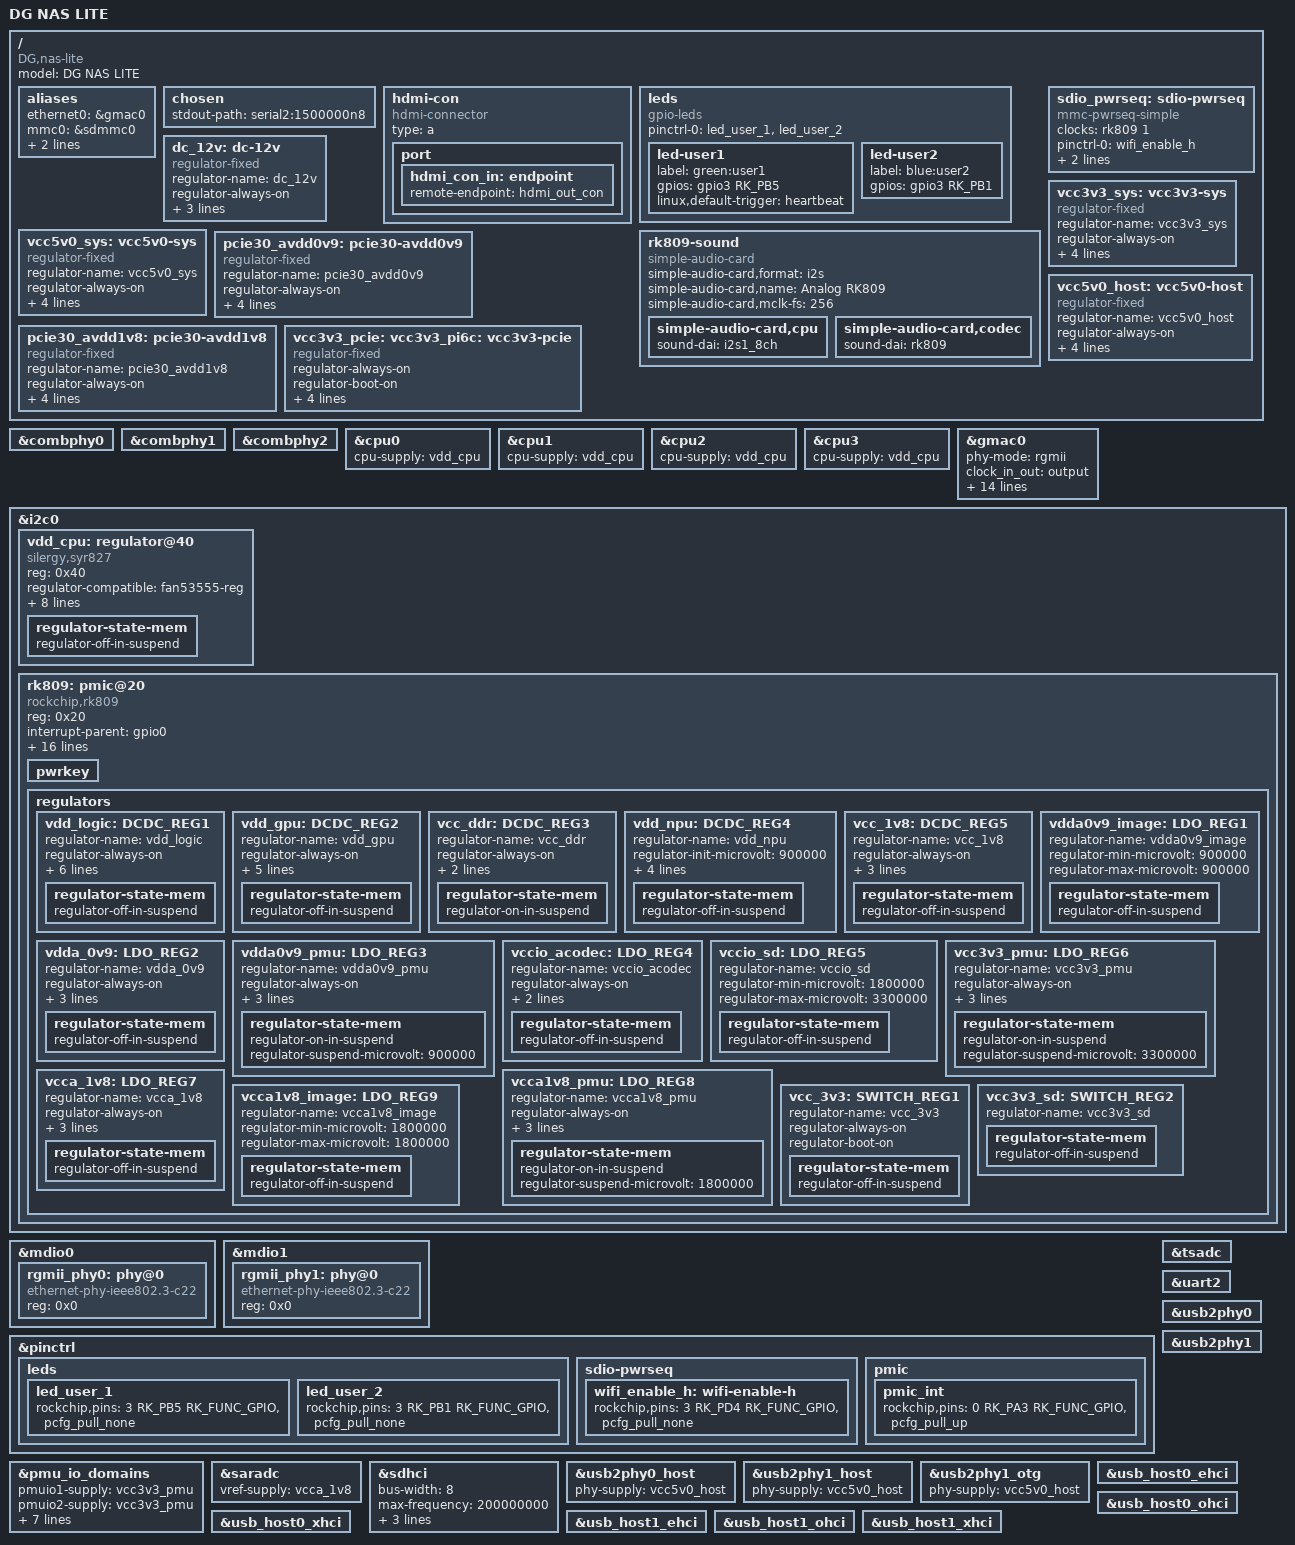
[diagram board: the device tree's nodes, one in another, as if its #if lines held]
// SPDX-License-Identifier: (GPL-2.0+ OR MIT)

/dts-v1/;
#include <dt-bindings/gpio/gpio.h>
#include <dt-bindings/leds/common.h>
#include <dt-bindings/pinctrl/rockchip.h>
#include <dt-bindings/soc/rockchip,vop2.h>
#include "rk3568.dtsi"

/ {
	model = "DG NAS LITE";
	compatible = "DG,nas-lite", "rockchip,rk3568";

	aliases {
		ethernet0 = &gmac0;
		mmc0 = &sdmmc0;
		mmc1 = &sdhci;
		mmc2 = &sdmmc1;
	};

	chosen: chosen {
		stdout-path = "serial2:1500000n8";
	};

#ifdef DTS_NO_LEGACY
	hdmi-con {
		compatible = "hdmi-connector";
		type = "a";

		port {
			hdmi_con_in: endpoint {
				remote-endpoint = <&hdmi_out_con>;
			};
		};
	};
#endif

	leds {
		compatible = "gpio-leds";
		pinctrl-names = "default";
		pinctrl-0 = <&led_user_1>, <&led_user_2>;

		led-user1 {
			label = "green:user1";
			gpios = <&gpio3 RK_PB5 GPIO_ACTIVE_HIGH>;
			linux,default-trigger = "heartbeat";
		};

		led-user2 {
			label = "blue:user2";
			gpios = <&gpio3 RK_PB1 GPIO_ACTIVE_HIGH>;
		};
	};

	rk809-sound {
		compatible = "simple-audio-card";
		simple-audio-card,format = "i2s";
		simple-audio-card,name = "Analog RK809";
		simple-audio-card,mclk-fs = <256>;

		simple-audio-card,cpu {
			sound-dai = <&i2s1_8ch>;
		};
		simple-audio-card,codec {
			sound-dai = <&rk809>;
		};
	};

	sdio_pwrseq: sdio-pwrseq {
		compatible = "mmc-pwrseq-simple";
		clocks = <&rk809 1>;
		clock-names = "ext_clock";
		pinctrl-names = "default";
		pinctrl-0 = <&wifi_enable_h>;
		reset-gpios = <&gpio3 RK_PD5 GPIO_ACTIVE_LOW>;
		post-power-on-delay-ms = <100>;
	};

	dc_12v: dc-12v {
		compatible = "regulator-fixed";
		regulator-name = "dc_12v";
		regulator-always-on;
		regulator-boot-on;
		regulator-min-microvolt = <12000000>;
		regulator-max-microvolt = <12000000>;
	};

	vcc3v3_sys: vcc3v3-sys {
		compatible = "regulator-fixed";
		regulator-name = "vcc3v3_sys";
		regulator-always-on;
		regulator-boot-on;
		regulator-min-microvolt = <3300000>;
		regulator-max-microvolt = <3300000>;
		vin-supply = <&dc_12v>;
	};

	vcc5v0_sys: vcc5v0-sys {
		compatible = "regulator-fixed";
		regulator-name = "vcc5v0_sys";
		regulator-always-on;
		regulator-boot-on;
		regulator-min-microvolt = <5000000>;
		regulator-max-microvolt = <5000000>;
		vin-supply = <&dc_12v>;
	};

	pcie30_avdd0v9: pcie30-avdd0v9 {
		compatible = "regulator-fixed";
		regulator-name = "pcie30_avdd0v9";
		regulator-always-on;
		regulator-boot-on;
		regulator-min-microvolt = <900000>;
		regulator-max-microvolt = <900000>;
		vin-supply = <&vcc3v3_sys>;
	};

	pcie30_avdd1v8: pcie30-avdd1v8 {
		compatible = "regulator-fixed";
		regulator-name = "pcie30_avdd1v8";
		regulator-always-on;
		regulator-boot-on;
		regulator-min-microvolt = <1800000>;
		regulator-max-microvolt = <1800000>;
		vin-supply = <&vcc3v3_sys>;
	};

	vcc3v3_pcie: vcc3v3_pi6c: vcc3v3-pcie {
		compatible = "regulator-fixed";
		regulator-always-on;
		regulator-boot-on;
		regulator-name = "vcc3v3_pcie";
		regulator-min-microvolt = <3300000>;
		regulator-max-microvolt = <3300000>;
		vin-supply = <&vcc5v0_sys>;
	};

	vcc5v0_host: vcc5v0-host {
		compatible = "regulator-fixed";
		regulator-name = "vcc5v0_host";
		regulator-always-on;
		regulator-boot-on;
		regulator-min-microvolt = <5000000>;
		regulator-max-microvolt = <5000000>;
		vin-supply = <&vcc5v0_sys>;
	};

};

&combphy0 {
	status = "okay";
};

&combphy1 {
	status = "okay";
};

&combphy2 {
	status = "okay";
};

&cpu0 {
	cpu-supply = <&vdd_cpu>;
};

&cpu1 {
	cpu-supply = <&vdd_cpu>;
};

&cpu2 {
	cpu-supply = <&vdd_cpu>;
};

&cpu3 {
	cpu-supply = <&vdd_cpu>;
};

&gmac0 {
	phy-mode = "rgmii";
	clock_in_out = "output";

	snps,reset-gpio = <&gpio3 RK_PA7 GPIO_ACTIVE_LOW>;
	snps,reset-active-low;
	/* Reset time is 20ms, 100ms for rtl8211f */
	snps,reset-delays-us = <0 20000 100000>;

	assigned-clocks = <&cru SCLK_GMAC0_RX_TX>, <&cru SCLK_GMAC0>;
	assigned-clock-parents = <&cru SCLK_GMAC0_RGMII_SPEED>;
	assigned-clock-rates = <0>, <125000000>;

	pinctrl-names = "default";
	pinctrl-0 = <&gmac0_miim
		     &gmac0_tx_bus2
		     &gmac0_rx_bus2
		     &gmac0_rgmii_clk
		     &gmac0_rgmii_bus
		     &gmac0_clkinout>;

	tx_delay = <0x3c>;
	rx_delay = <0x2f>;

	phy-handle = <&rgmii_phy0>;
	status = "okay";
};

&i2c0 {
	status = "okay";

	vdd_cpu: regulator@40 {
		compatible = "silergy,syr827";
		reg = <0x40>;
		regulator-compatible = "fan53555-reg";
		fcs,suspend-voltage-selector = <1>;
		regulator-name = "vdd_cpu";
		regulator-always-on;
		regulator-boot-on;
		regulator-min-microvolt = <712500>;
		regulator-max-microvolt = <1390000>;
		regulator-ramp-delay = <2300>;
		vin-supply = <&vcc5v0_sys>;

		regulator-state-mem {
			regulator-off-in-suspend;
		};
	};

	rk809: pmic@20 {
		compatible = "rockchip,rk809";
		reg = <0x20>;
		interrupt-parent = <&gpio0>;
		interrupts = <RK_PA3 IRQ_TYPE_LEVEL_LOW>;
		assigned-clocks = <&cru I2S1_MCLKOUT_TX>;
		assigned-clock-parents = <&cru CLK_I2S1_8CH_TX>;
		#clock-cells = <1>;
		clock-names = "mclk";
		clocks = <&cru I2S1_MCLKOUT_TX>;
		pinctrl-names = "default";
		pinctrl-0 = <&pmic_int>;
		rockchip,system-power-controller;
		#sound-dai-cells = <0>;
		vcc1-supply = <&vcc3v3_sys>;
		vcc2-supply = <&vcc3v3_sys>;
		vcc3-supply = <&vcc3v3_sys>;
		vcc4-supply = <&vcc3v3_sys>;
		vcc5-supply = <&vcc3v3_sys>;
		vcc6-supply = <&vcc3v3_sys>;
		vcc7-supply = <&vcc3v3_sys>;
		vcc8-supply = <&vcc3v3_sys>;
		vcc9-supply = <&vcc3v3_sys>;
		wakeup-source;
		pwrkey {
				status = "okay";
			};
		regulators {
			vdd_logic: DCDC_REG1 {
				regulator-name = "vdd_logic";
				regulator-always-on;
				regulator-boot-on;
				regulator-init-microvolt = <900000>;
				regulator-initial-mode = <0x2>;
				regulator-min-microvolt = <500000>;
				regulator-max-microvolt = <1350000>;
				regulator-ramp-delay = <6001>;

				regulator-state-mem {
					regulator-off-in-suspend;
				};
			};

			vdd_gpu: DCDC_REG2 {
				regulator-name = "vdd_gpu";
				regulator-always-on;
				regulator-init-microvolt = <900000>;
				regulator-initial-mode = <0x2>;
				regulator-min-microvolt = <500000>;
				regulator-max-microvolt = <1350000>;
				regulator-ramp-delay = <6001>;

				regulator-state-mem {
					regulator-off-in-suspend;
				};
			};

			vcc_ddr: DCDC_REG3 {
				regulator-name = "vcc_ddr";
				regulator-always-on;
				regulator-boot-on;
				regulator-initial-mode = <0x2>;

				regulator-state-mem {
					regulator-on-in-suspend;
				};
			};

			vdd_npu: DCDC_REG4 {
				regulator-name = "vdd_npu";
				regulator-init-microvolt = <900000>;
				regulator-initial-mode = <0x2>;
				regulator-min-microvolt = <500000>;
				regulator-max-microvolt = <1350000>;
				regulator-ramp-delay = <6001>;

				regulator-state-mem {
					regulator-off-in-suspend;
				};
			};

			vcc_1v8: DCDC_REG5 {
				regulator-name = "vcc_1v8";
				regulator-always-on;
				regulator-boot-on;
				regulator-min-microvolt = <1800000>;
				regulator-max-microvolt = <1800000>;

				regulator-state-mem {
					regulator-off-in-suspend;
				};
			};

			vdda0v9_image: LDO_REG1 {
				regulator-name = "vdda0v9_image";
				regulator-min-microvolt = <900000>;
				regulator-max-microvolt = <900000>;

				regulator-state-mem {
					regulator-off-in-suspend;
				};
			};

			vdda_0v9: LDO_REG2 {
				regulator-name = "vdda_0v9";
				regulator-always-on;
				regulator-boot-on;
				regulator-min-microvolt = <900000>;
				regulator-max-microvolt = <900000>;

				regulator-state-mem {
					regulator-off-in-suspend;
				};
			};

			vdda0v9_pmu: LDO_REG3 {
				regulator-name = "vdda0v9_pmu";
				regulator-always-on;
				regulator-boot-on;
				regulator-min-microvolt = <900000>;
				regulator-max-microvolt = <900000>;

				regulator-state-mem {
					regulator-on-in-suspend;
					regulator-suspend-microvolt = <900000>;
				};
			};

			vccio_acodec: LDO_REG4 {
				regulator-name = "vccio_acodec";
				regulator-always-on;
				regulator-min-microvolt = <3300000>;
				regulator-max-microvolt = <3300000>;

				regulator-state-mem {
					regulator-off-in-suspend;
				};
			};

			vccio_sd: LDO_REG5 {
				regulator-name = "vccio_sd";
				regulator-min-microvolt = <1800000>;
				regulator-max-microvolt = <3300000>;

				regulator-state-mem {
					regulator-off-in-suspend;
				};
			};

			vcc3v3_pmu: LDO_REG6 {
				regulator-name = "vcc3v3_pmu";
				regulator-always-on;
				regulator-boot-on;
				regulator-min-microvolt = <3300000>;
				regulator-max-microvolt = <3300000>;

				regulator-state-mem {
					regulator-on-in-suspend;
					regulator-suspend-microvolt = <3300000>;
				};
			};

			vcca_1v8: LDO_REG7 {
				regulator-name = "vcca_1v8";
				regulator-always-on;
				regulator-boot-on;
				regulator-min-microvolt = <1800000>;
				regulator-max-microvolt = <1800000>;

				regulator-state-mem {
					regulator-off-in-suspend;
				};
			};

			vcca1v8_pmu: LDO_REG8 {
				regulator-name = "vcca1v8_pmu";
				regulator-always-on;
				regulator-boot-on;
				regulator-min-microvolt = <1800000>;
				regulator-max-microvolt = <1800000>;

				regulator-state-mem {
					regulator-on-in-suspend;
					regulator-suspend-microvolt = <1800000>;
				};
			};

			vcca1v8_image: LDO_REG9 {
				regulator-name = "vcca1v8_image";
				regulator-min-microvolt = <1800000>;
				regulator-max-microvolt = <1800000>;

				regulator-state-mem {
					regulator-off-in-suspend;
				};
			};

			vcc_3v3: SWITCH_REG1 {
				regulator-name = "vcc_3v3";
				regulator-always-on;
				regulator-boot-on;

				regulator-state-mem {
					regulator-off-in-suspend;
				};
			};

			vcc3v3_sd: SWITCH_REG2 {
				regulator-name = "vcc3v3_sd";

				regulator-state-mem {
					regulator-off-in-suspend;
				};
			};
		};
	};
};


&mdio0 {
	rgmii_phy0: phy@0 {
		compatible = "ethernet-phy-ieee802.3-c22";
		reg = <0x0>;
	};
};

&mdio1 {
	rgmii_phy1: phy@0 {
		compatible = "ethernet-phy-ieee802.3-c22";
		reg = <0x0>;
	};
};

&pinctrl {
	leds {
		led_user_1: led_user_1 {
			rockchip,pins = <3 RK_PB5 RK_FUNC_GPIO &pcfg_pull_none>;
		};

		led_user_2: led_user_2 {
			rockchip,pins = <3 RK_PB1 RK_FUNC_GPIO &pcfg_pull_none>;
		};
	};

	sdio-pwrseq {
		wifi_enable_h: wifi-enable-h {
			rockchip,pins = <3 RK_PD4 RK_FUNC_GPIO &pcfg_pull_none>;
		};
	};

	pmic {
		pmic_int: pmic_int {
			rockchip,pins = <0 RK_PA3 RK_FUNC_GPIO &pcfg_pull_up>;
		};
	};
};

&pmu_io_domains {
	pmuio1-supply = <&vcc3v3_pmu>;
	pmuio2-supply = <&vcc3v3_pmu>;
	vccio1-supply = <&vccio_acodec>;
	vccio2-supply = <&vcc_1v8>;
	vccio3-supply = <&vccio_sd>;
	vccio4-supply = <&vcc_1v8>;
	vccio5-supply = <&vcc_3v3>;
	vccio6-supply = <&vcc_1v8>;
	vccio7-supply = <&vcc_3v3>;
	status = "okay";
};


&saradc {
	vref-supply = <&vcca_1v8>;
	status = "okay";
};


&sdhci {
	bus-width = <8>;
	max-frequency = <200000000>;
	non-removable;
	pinctrl-names = "default";
	pinctrl-0 = <&emmc_bus8 &emmc_clk &emmc_cmd &emmc_datastrobe>;
	status = "okay";
};


&tsadc {
	status = "okay";
};

&uart2 {
	status = "okay";
};

&usb2phy0_host {
	phy-supply = <&vcc5v0_host>;
	status = "okay";
};

&usb2phy1_host {
	phy-supply = <&vcc5v0_host>;
	status = "okay";
};

&usb2phy1_otg {
	phy-supply = <&vcc5v0_host>;
	status = "okay";
};

&usb2phy0 {
	status = "okay";
};

&usb2phy1 {
	status = "okay";
};

&usb_host0_ehci {
	status = "okay";
};

&usb_host0_ohci {
	status = "okay";
};

&usb_host0_xhci {
	status = "okay";
};

&usb_host1_ehci {
	status = "okay";
};

&usb_host1_ohci {
	status = "okay";
};

&usb_host1_xhci {
	status = "okay";
};

